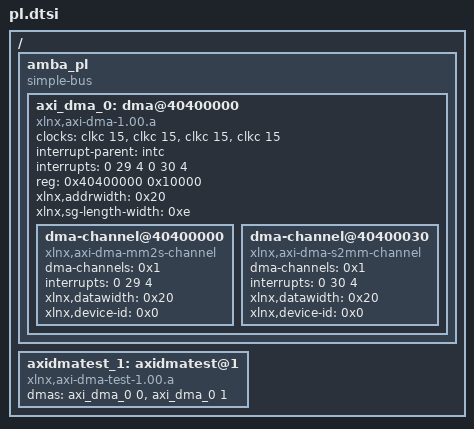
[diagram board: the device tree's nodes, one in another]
/*
 * CAUTION: This file is automatically generated by Xilinx.
 * Version: HSI 2018.2
 * Today is: Fri Dec  7 20:04:06 2018
 */


/ {
	amba_pl: amba_pl {
		#address-cells = <1>;
		#size-cells = <1>;
		compatible = "simple-bus";
		ranges ;
		axi_dma_0: dma@40400000 {
			#dma-cells = <1>;
			clock-names = "s_axi_lite_aclk", "m_axi_sg_aclk", "m_axi_mm2s_aclk", "m_axi_s2mm_aclk";
			clocks = <&clkc 15>, <&clkc 15>, <&clkc 15>, <&clkc 15>;
			compatible = "xlnx,axi-dma-1.00.a";
			interrupt-names = "mm2s_introut", "s2mm_introut";
			interrupt-parent = <&intc>;
			interrupts = <0 29 4 0 30 4>;
			reg = <0x40400000 0x10000>;
			xlnx,addrwidth = <0x20>;
			xlnx,sg-length-width = <0xe>;
			dma-channel@40400000 {
				compatible = "xlnx,axi-dma-mm2s-channel";
				dma-channels = <0x1>;
				interrupts = <0 29 4>;
				xlnx,datawidth = <0x20>;
				xlnx,device-id = <0x0>;
			};
			dma-channel@40400030 {
				compatible = "xlnx,axi-dma-s2mm-channel";
				dma-channels = <0x1>;
				interrupts = <0 30 4>;
				xlnx,datawidth = <0x20>;
				xlnx,device-id = <0x0>;
			};
		};
	};
  axidmatest_1: axidmatest@1 {
    compatible ="xlnx,axi-dma-test-1.00.a";
    dmas = <&axi_dma_0 0
            &axi_dma_0 1>; 
    dma-names = "axidma0", "axidma1";
  };
};
